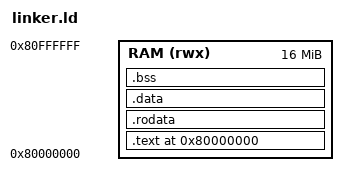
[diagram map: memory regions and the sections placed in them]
OUTPUT_ARCH(riscv)
ENTRY(_start)

MEMORY
{
    RAM (rwx) : ORIGIN = 0x80000000, LENGTH = 16M
}

SECTIONS
{
    . = 0x80000000;

    .text : {
        *(.text.init)
        *(.text .text.*)
    } > RAM

    .rodata : {
        *(.rodata .rodata.*)
    } > RAM

    .data : {
        *(.data .data.*)
    } > RAM

    .bss : {
        __bss_start = .;
        *(.bss .bss.*)
        *(COMMON)
        __bss_end = .;
    } > RAM
}
